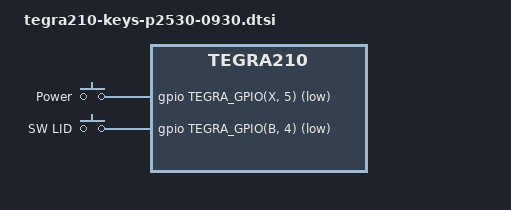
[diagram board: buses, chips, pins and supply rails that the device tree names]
#include <dt-bindings/gpio/tegra-gpio.h>
#include <dt-bindings/input/input.h>

/ {
	gpio-keys {
		compatible = "gpio-keys";
		gpio-keys,name = "gpio-keys";

		power {
			label = "Power";
			gpios = <&gpio TEGRA_GPIO(X, 5) GPIO_ACTIVE_LOW>;
			linux,code = <KEY_POWER>;
			gpio-key,wakeup;
		};

		sw_lid {
			label = "SW LID";
			gpios = <&gpio TEGRA_GPIO(B, 4) GPIO_ACTIVE_LOW>;
			linux,code = <SW_LID>;
			linux,input-type = <EV_SW>;
			gpio-key,wakeup;
			debounce-interval = <300>;
		};
	};
};
